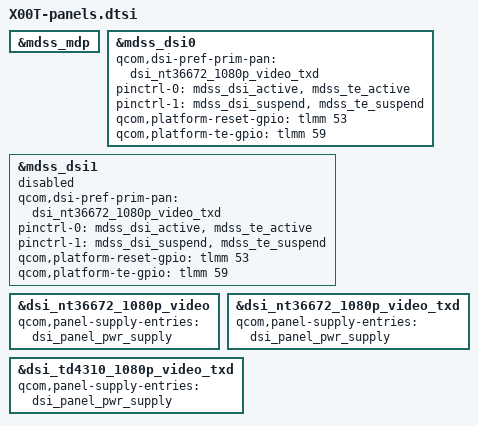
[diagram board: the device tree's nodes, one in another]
/*
 * Copyright (c) 2019, The Linux Foundation. All rights reserved.
 *
 * This program is free software; you can redistribute it and/or modify
 * it under the terms of the GNU General Public License version 2 and
 * only version 2 as published by the Free Software Foundation.
 *
 * This program is distributed in the hope that it will be useful,
 * but WITHOUT ANY WARRANTY; without even the implied warranty of
 * MERCHANTABILITY or FITNESS FOR A PARTICULAR PURPOSE.  See the
 * GNU General Public License for more details.
 */

#include "panels/dsi-panel-auo-ft8716f-5p9-fhd-video.dtsi"
#include "panels/dsi-panel-nt36672-1080p-video.dtsi"
#include "panels/dsi-panel-nt36672-1080p-video-txd.dtsi"
#include "panels/dsi-panel-td4310-1080p-video-txd.dtsi"

/* Remove unused panels */
&mdss_mdp {
	/delete-node/ qcom,mdss_dsi_dual_sim_video;
	/delete-node/ qcom,mdss_dsi_nt35695b_truly_fhd_video;
	/delete-node/ qcom,mdss_dsi_nt35695b_truly_fhd_cmd;
	/delete-node/ qcom,mdss_dsi_rm67195_amoled_fhd_cmd;
	/delete-node/ qcom,mdss_dsi_nt35597_dsc_video_truly;
	/delete-node/ qcom,mdss_dsi_nt35597_truly_wqxga_cmd;
	/delete-node/ qcom,mdss_dsi_nt35597_wqxga_cmd;
	/delete-node/ qcom,mdss_dsi_nt35597_wqxga_video;
	/delete-node/ qcom,mdss_dsi_nt35597_dsc_cmd_truly;
	/delete-node/ qcom,mdss_dsi_lgd_incell_sw49106_fhd_video;
	/delete-node/ qcom,mdss_dsi_nt35597_wqxga_video_truly;
	/delete-node/ qcom,mdss_dsi_nt36850_truly_wqhd_cmd;
	/delete-node/ qcom,mdss_dsi_sharp_wqxga_video;
	/delete-node/ qcom,mdss_dsi_sim_video;
	/delete-node/ qcom,mdss_dsi_truly_1080p_cmd;
	/delete-node/ qcom,mdss_dsi_truly_1080p_video;
	/delete-node/ qcom,mdss_dsi_hx8399_truly_fhd_video;
};

&mdss_dsi0 {
	qcom,dsi-pref-prim-pan = <&dsi_nt36672_1080p_video_txd>;
	pinctrl-names = "mdss_default", "mdss_sleep";
	pinctrl-0 = <&mdss_dsi_active &mdss_te_active>;
	pinctrl-1 = <&mdss_dsi_suspend &mdss_te_suspend>;
	qcom,platform-reset-gpio = <&tlmm 53 0>;
	qcom,platform-te-gpio = <&tlmm 59 0>;
};

&mdss_dsi1 {
	qcom,dsi-pref-prim-pan = <&dsi_nt36672_1080p_video_txd>;
	pinctrl-names = "mdss_default", "mdss_sleep";
	pinctrl-0 = <&mdss_dsi_active &mdss_te_active>;
	pinctrl-1 = <&mdss_dsi_suspend &mdss_te_suspend>;
	qcom,platform-reset-gpio = <&tlmm 53 0>;
	qcom,platform-te-gpio = <&tlmm 59 0>;
	status = "disabled";
};

&dsi_nt36672_1080p_video {
	qcom,panel-supply-entries = <&dsi_panel_pwr_supply>;
};

&dsi_nt36672_1080p_video_txd {
	qcom,panel-supply-entries = <&dsi_panel_pwr_supply>;
};

&dsi_td4310_1080p_video_txd {
	qcom,panel-supply-entries = <&dsi_panel_pwr_supply>;
};
